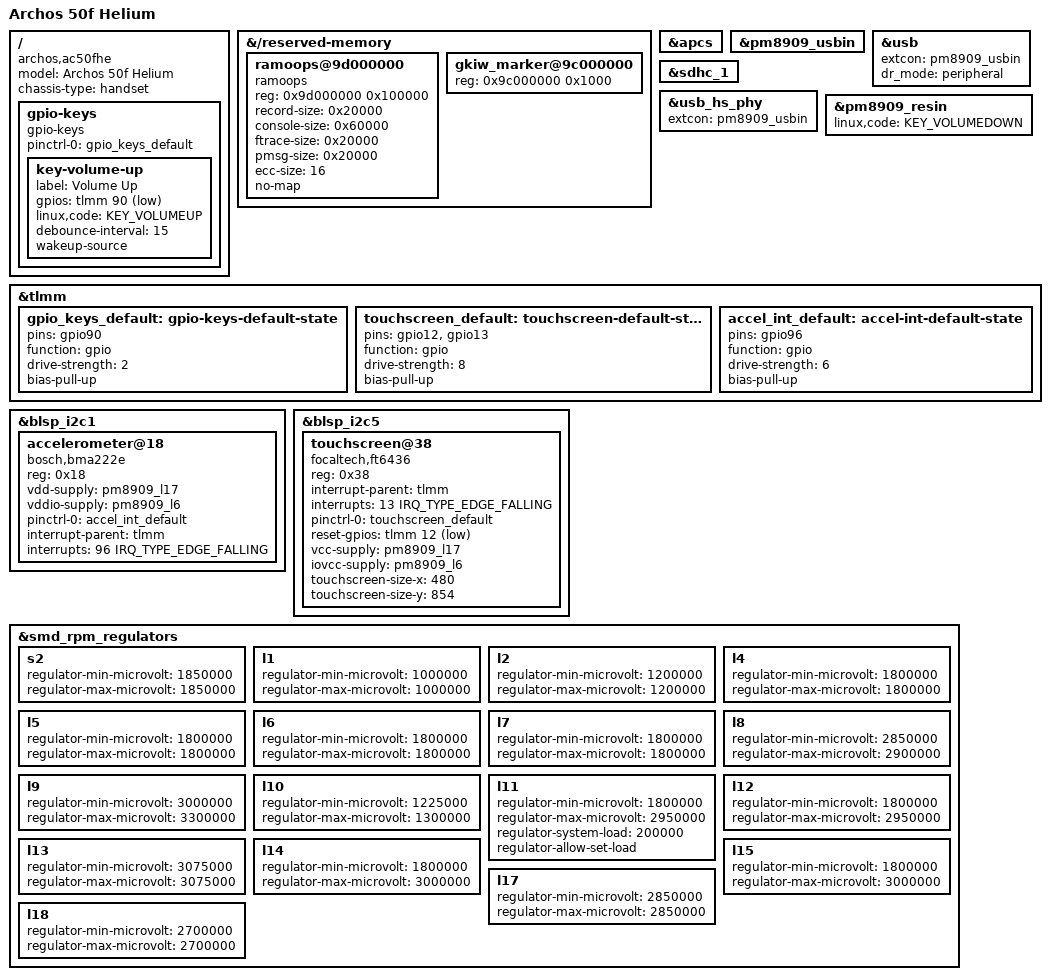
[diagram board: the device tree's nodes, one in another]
// SPDX-License-Identifier: GPL-2.0-only
/*
 * Archos 50f Helium (AC50FHE), MSM8909.
 *
 * Minimal development tree: peripheral-mode USB (ChipIdea + ULPI PHY),
 * the PM8909 regulators needed by the PHY, and ramoops for kernel logs.
 * Storage, display and the modem are intentionally left disabled.
 */

/dts-v1/;

#include "qcom-msm8909-pm8909.dtsi"

/ {
	model = "Archos 50f Helium";
	compatible = "archos,ac50fhe", "qcom,msm8909";
	chassis-type = "handset";

};

&{/reserved-memory} {
	ramoops@9d000000 {
		compatible = "ramoops";
		reg = <0x9d000000 0x100000>;
		record-size = <0x20000>;
		console-size = <0x60000>;
		ftrace-size = <0x20000>;
		pmsg-size = <0x20000>;
		ecc-size = <16>;
		no-map;
	};

	/* Mapped and reserved: the initramfs writes boot-progress markers here. */
	gkiw_marker@9c000000 {
		reg = <0x9c000000 0x1000>;
	};
};

/*
 * The APC mailbox driver only needs the IPC register window.  The "pll" and
 * "aux" clocks listed in the SoC dtsi are consumed by the APCS CPU clock
 * driver, which we do not use (the A53 PLL block does not respond on this
 * MSM8909 and hangs the boot).  Drop them so fw_devlink does not block the
 * mailbox on the a7pll supplier.
 */
&apcs {
	/delete-property/ clocks;
	/delete-property/ clock-names;
};

&pm8909_usbin {
	status = "okay";
};

&usb {
	extcon = <&pm8909_usbin>;
	dr_mode = "peripheral";
	status = "okay";
};

&sdhc_1 {
	status = "okay";
};

&usb_hs_phy {
	/* v1p8/v3p3 supplies come from qcom-msm8909-pm8909.dtsi (L7/L13). */
	extcon = <&pm8909_usbin>;
};

/* Volume Down is wired to the PMIC resin input. */
&pm8909_resin {
	linux,code = <KEY_VOLUMEDOWN>;
	status = "okay";
};

/ {
	gpio-keys {
		compatible = "gpio-keys";
		pinctrl-names = "default";
		pinctrl-0 = <&gpio_keys_default>;

		key-volume-up {
			label = "Volume Up";
			gpios = <&tlmm 90 GPIO_ACTIVE_LOW>;
			linux,code = <KEY_VOLUMEUP>;
			debounce-interval = <15>;
			wakeup-source;
		};
	};
};

&tlmm {
	gpio_keys_default: gpio-keys-default-state {
		pins = "gpio90";
		function = "gpio";
		drive-strength = <2>;
		bias-pull-up;
	};

	touchscreen_default: touchscreen-default-state {
		pins = "gpio12", "gpio13";
		function = "gpio";
		drive-strength = <8>;
		bias-pull-up;
	};

	accel_int_default: accel-int-default-state {
		pins = "gpio96";
		function = "gpio";
		drive-strength = <6>;
		bias-pull-up;
	};
};

&blsp_i2c1 {
	status = "okay";

	accelerometer@18 {
		compatible = "bosch,bma222e";
		reg = <0x18>;
		vdd-supply = <&pm8909_l17>;
		vddio-supply = <&pm8909_l6>;
		pinctrl-names = "default";
		pinctrl-0 = <&accel_int_default>;
		interrupt-parent = <&tlmm>;
		interrupts = <96 IRQ_TYPE_EDGE_FALLING>;
	};
};

&blsp_i2c5 {
	status = "okay";

	touchscreen@38 {
		compatible = "focaltech,ft6436";
		reg = <0x38>;
		interrupt-parent = <&tlmm>;
		interrupts = <13 IRQ_TYPE_EDGE_FALLING>;
		pinctrl-names = "default";
		pinctrl-0 = <&touchscreen_default>;
		reset-gpios = <&tlmm 12 GPIO_ACTIVE_LOW>;
		vcc-supply = <&pm8909_l17>;
		iovcc-supply = <&pm8909_l6>;
		touchscreen-size-x = <480>;
		touchscreen-size-y = <854>;
	};
};

&smd_rpm_regulators {
	s2 {
		regulator-min-microvolt = <1850000>;
		regulator-max-microvolt = <1850000>;
	};

	l1 {
		regulator-min-microvolt = <1000000>;
		regulator-max-microvolt = <1000000>;
	};

	l2 {
		regulator-min-microvolt = <1200000>;
		regulator-max-microvolt = <1200000>;
	};

	l4 {
		regulator-min-microvolt = <1800000>;
		regulator-max-microvolt = <1800000>;
	};

	l5 {
		regulator-min-microvolt = <1800000>;
		regulator-max-microvolt = <1800000>;
	};

	l6 {
		regulator-min-microvolt = <1800000>;
		regulator-max-microvolt = <1800000>;
	};

	l7 {
		regulator-min-microvolt = <1800000>;
		regulator-max-microvolt = <1800000>;
	};

	l8 {
		regulator-min-microvolt = <2850000>;
		regulator-max-microvolt = <2900000>;
	};

	l9 {
		regulator-min-microvolt = <3000000>;
		regulator-max-microvolt = <3300000>;
	};

	l10 {
		regulator-min-microvolt = <1225000>;
		regulator-max-microvolt = <1300000>;
	};

	l11 {
		regulator-min-microvolt = <1800000>;
		regulator-max-microvolt = <2950000>;
		regulator-system-load = <200000>;
		regulator-allow-set-load;
	};

	l12 {
		regulator-min-microvolt = <1800000>;
		regulator-max-microvolt = <2950000>;
	};

	l13 {
		regulator-min-microvolt = <3075000>;
		regulator-max-microvolt = <3075000>;
	};

	l14 {
		regulator-min-microvolt = <1800000>;
		regulator-max-microvolt = <3000000>;
	};

	l15 {
		regulator-min-microvolt = <1800000>;
		regulator-max-microvolt = <3000000>;
	};

	l17 {
		regulator-min-microvolt = <2850000>;
		regulator-max-microvolt = <2850000>;
	};

	l18 {
		regulator-min-microvolt = <2700000>;
		regulator-max-microvolt = <2700000>;
	};
};
